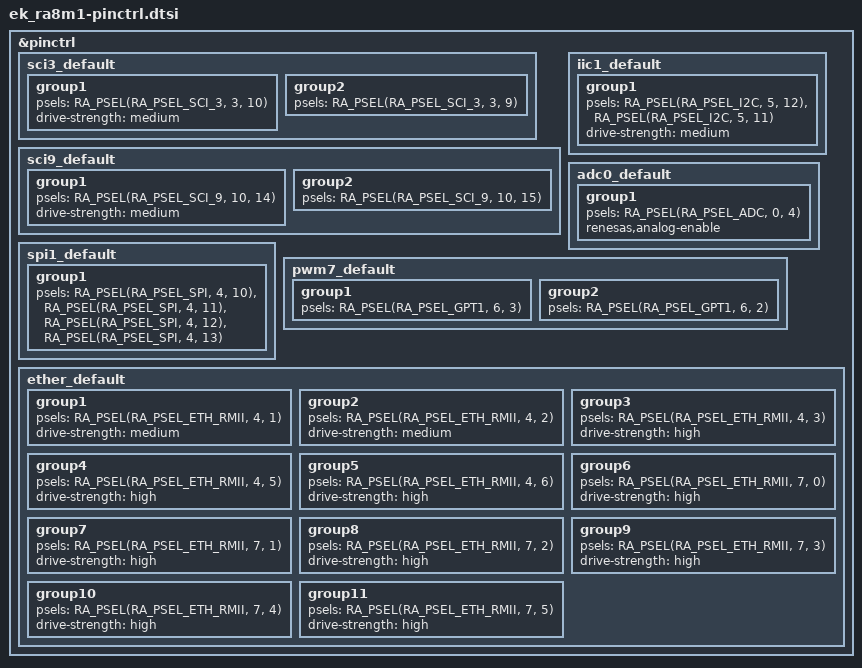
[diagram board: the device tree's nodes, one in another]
/*
 * Copyright (c) 2024 Renesas Electronics Corporation
 * SPDX-License-Identifier: Apache-2.0
 */

&pinctrl {
	sci3_default: sci3_default {
		group1 {
			/* tx */
			psels = <RA_PSEL(RA_PSEL_SCI_3, 3, 10)>;
			drive-strength = "medium";
		};
		group2 {
			/* rx */
			psels = <RA_PSEL(RA_PSEL_SCI_3, 3, 9)>;
		};
	};

	sci9_default: sci9_default {
		group1 {
			/* tx */
			psels = <RA_PSEL(RA_PSEL_SCI_9, 10, 14)>;
			drive-strength = "medium";
		};
		group2 {
			/* rx */
			psels = <RA_PSEL(RA_PSEL_SCI_9, 10, 15)>;
		};
	};

	iic1_default: iic1_default {
		group1 {
			/* SCL1 SDA1*/
			psels = <RA_PSEL(RA_PSEL_I2C, 5, 12)>,<RA_PSEL(RA_PSEL_I2C, 5, 11)>;
			drive-strength = "medium";
		};
	};

	adc0_default: adc0_default {
		group1 {
			/* input */
			psels = <RA_PSEL(RA_PSEL_ADC, 0, 4)>;
			renesas,analog-enable;
		};
	};

	spi1_default: spi1_default {
		group1 {
			/* MISO MOSI RSPCK SSL*/
			psels = <RA_PSEL(RA_PSEL_SPI, 4, 10)>,
			<RA_PSEL(RA_PSEL_SPI, 4, 11)>,
			<RA_PSEL(RA_PSEL_SPI, 4, 12)>,
			<RA_PSEL(RA_PSEL_SPI, 4, 13)>;
		};
	};

	pwm7_default: pwm7_default {
		group1 {
			/* GTIOC7A */
			psels = <RA_PSEL(RA_PSEL_GPT1, 6, 3)>;
		};
		group2 {
			/* GTIOC7B */
			psels = <RA_PSEL(RA_PSEL_GPT1, 6, 2)>;
		};
	};

	ether_default: ether_default {
		group1 {
			/* ET0_MDC */
			psels = <RA_PSEL(RA_PSEL_ETH_RMII, 4, 1)>;
			drive-strength = "medium";
		};
		group2 {
			/* ET0_MDIO */
			psels = <RA_PSEL(RA_PSEL_ETH_RMII, 4, 2)>;
			drive-strength = "medium";
		};
		group3 {
			/* ET0_LINKSTA */
			psels = <RA_PSEL(RA_PSEL_ETH_RMII, 4, 3)>;
			drive-strength = "high";
		};
		group4 {
			/* RMII0_TXD_EN */
			psels = <RA_PSEL(RA_PSEL_ETH_RMII, 4, 5)>;
			drive-strength = "high";
		};
		group5 {
			/* RMII0_TXD1 */
			psels = <RA_PSEL(RA_PSEL_ETH_RMII, 4, 6)>;
			drive-strength = "high";
		};
		group6 {
			/* RMII0_TXD0 */
			psels = <RA_PSEL(RA_PSEL_ETH_RMII, 7, 0)>;
			drive-strength = "high";
		};
		group7 {
			/* REF50CK0 */
			psels = <RA_PSEL(RA_PSEL_ETH_RMII, 7, 1)>;
			drive-strength = "high";
		};
		group8 {
			/* RMII0_RXD0 */
			psels = <RA_PSEL(RA_PSEL_ETH_RMII, 7, 2)>;
			drive-strength = "high";
		};
		group9 {
			/* RMII0_RXD1 */
			psels = <RA_PSEL(RA_PSEL_ETH_RMII, 7, 3)>;
			drive-strength = "high";
		};
		group10 {
			/* RMII0_RX_ER */
			psels = <RA_PSEL(RA_PSEL_ETH_RMII, 7, 4)>;
			drive-strength = "high";
		};
		group11 {
			/* RMII0_CRS_DV */
			psels = <RA_PSEL(RA_PSEL_ETH_RMII, 7, 5)>;
			drive-strength = "high";
		};
	};
};
